# EFR32FG23B021F512IM48 register map
Vendor: Silicon Labs; Series: EFR32; File version: C
CPU: CM33 r0p4, little endian, MPU, FPU, DSP, VTOR, 4 interrupt priority bits, 8 SAU regions
Registers are 32-bit, read-write, reset 0x0 unless marked. A register's access mark holds for its fields unless they carry their own. Offsets are from the block's base; [hi:lo] are bit positions; 'fields as' and 'values as' point back to an identical list.

## PCNT0_NS — PCNT0_NS Registers
Base 0x59030000
Same registers: PCNT0_S 0x49030000
0x00 IPVERSION ro reset 0x1
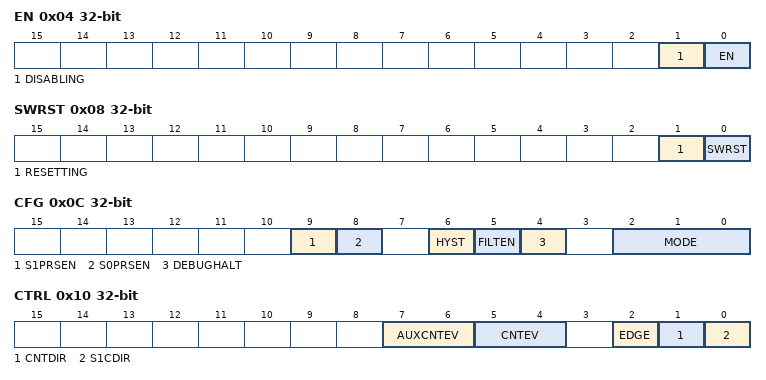
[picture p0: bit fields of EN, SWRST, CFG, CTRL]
0x04 EN
  [1] DISABLING ro — Disablement busy status
  [0] EN — PCNT Module Enable
0x08 SWRST
  [1] RESETTING ro — Software reset busy status
  [0] SWRST wo — Software reset command
0x0C CFG
  [9] S1PRSEN — S1IN PRS Enable
  [8] S0PRSEN — S0IN PRS Enable
  [6] HYST — Enable Hysteresis
  [5] FILTEN — Enable Digital Pulse Width Filter
  [4] DEBUGHALT — Debug Mode Halt Enable
    0=DISABLE (PCNT is running in debug mode.); 1=ENABLE (PCNT is frozen in debug mode.)
  [2:0] MODE — Mode Select
    0=OVSSINGLE (Single input EM23GRPACLK oversampling mode (available in EM0-EM3).); 1=EXTCLKSINGLE (Externally clocked single input counter mode (available in EM0-EM3).); 2=EXTCLKQUAD (Externally clocked quadrature decoder mode (available in EM0-EM3).); 3=OVSQUAD1X (EM23GRPACLK oversampling quadrature decoder 1X mode (available in EM0-EM3).); 4=OVSQUAD2X (EM23GRPACLK oversampling quadrature decoder 2X mode (available in EM0-EM3).); 5=OVSQUAD4X (EM23GRPACLK oversampling quadrature decoder 4X mode (available in EM0-EM3).)
0x10 CTRL
  [7:6] AUXCNTEV — Controls When the Aux Counter Counts
    0=BOTH (Counts up on both up-count and down-count events.); 1=UP (Counts up on up-count events.); 2=DOWN (Counts up on down-count events.)
  [5:4] CNTEV — Controls When the Counter Counts
    0=BOTH (Counts up on up-count and down on down-count events.); 1=UP (Only counts up on up-count events.); 2=DOWN (Only counts down on down-count events.)
  [2] EDGE — Edge Select
    0=POS (Positive edges on the PCNTn_S0IN inputs are counted in OVSSINGLE mode. Does not invert PCNTn_S1IN input in OVSSINGLE and EXTCLKSINGLE modes); 1=NEG (Negative edges on the PCNTn_S0IN inputs are counted in OVSSINGLE mode. Inverts the PCNTn_S1IN input in OVSSINGLE and EXTCLKSINGLE modes)
  [1] CNTDIR — Non-Quadrature Mode Counter Direction Co
    0=UP (Up counter mode.); 1=DOWN (Down counter mode.)
  [0] S1CDIR — Count Direction Determined By S1
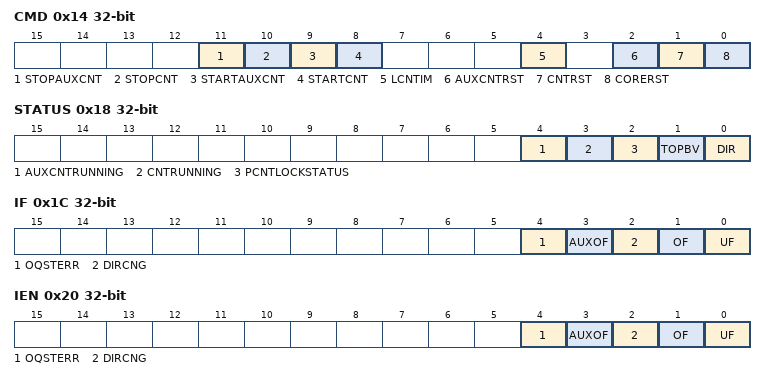
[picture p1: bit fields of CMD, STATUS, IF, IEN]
0x14 CMD wo
  [11] STOPAUXCNT — Stop Aux Counter
  [10] STOPCNT — Stop Main Counter
  [9] STARTAUXCNT — Start Aux Counter
  [8] STARTCNT — Start Main Counter
  [4] LCNTIM — Load CNT Immediately
  [2] AUXCNTRST — AUXCNT Reset
  [1] CNTRST — CNT Reset
  [0] CORERST — PCNT Clock Domain Reset
0x18 STATUS ro
  [4] AUXCNTRUNNING — Aux Counter running status
  [3] CNTRUNNING — Main Counter running status
  [2] PCNTLOCKSTATUS — Lock Status
    0=UNLOCKED (PCNT registers are unlocked); 1=LOCKED (PCNT registers are locked)
  [1] TOPBV — TOP Buffer Valid
  [0] DIR — Current Counter Direction
    0=UP (Up counter mode (clockwise in EXTCLKQUAD mode with the EDGE bit in PCNTn_CTRL set to 0).); 1=DOWN (Down counter mode.)
0x1C IF
  [4] OQSTERR — Oversampling Quad State Err Int Flag
  [3] AUXOF — Auxiliary Overflow Interrupt Read Flag
  [2] DIRCNG — Direction Change Detect Interrupt Flag
  [1] OF — Overflow Interrupt Read Flag
  [0] UF — Underflow Interrupt Read Flag
0x20 IEN
  fields as IF
0x24 CNT ro
  [15:0] CNT — Counter Value
0x28 AUXCNT ro
  [15:0] AUXCNT — Auxiliary Counter Value
0x2C TOP reset 0xFF
  [15:0] TOP — Counter Top Value
0x30 TOPB reset 0xFF
  [15:0] TOPB — Counter Top Buffer Register
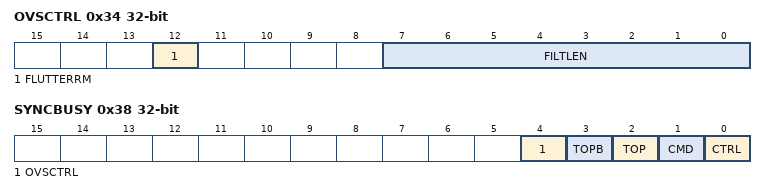
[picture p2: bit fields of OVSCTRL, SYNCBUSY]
0x34 OVSCTRL
  [12] FLUTTERRM — Flutter Remove
  [7:0] FILTLEN — Configure Filter Length for Inputs S0IN
0x38 SYNCBUSY ro
  [4] OVSCTRL — OVSCTRL Register Busy
  [3] TOPB — TOPB Register Busy
  [2] TOP — TOP Register Busy
  [1] CMD — CMD Register Busy
  [0] CTRL — CTRL Register Busy
0x3C LOCK wo
  [15:0] PCNTLOCKKEY — Configuration Lock Key
    0xA7E0=UNLOCK (Write to unock PCNT lockable registers)
